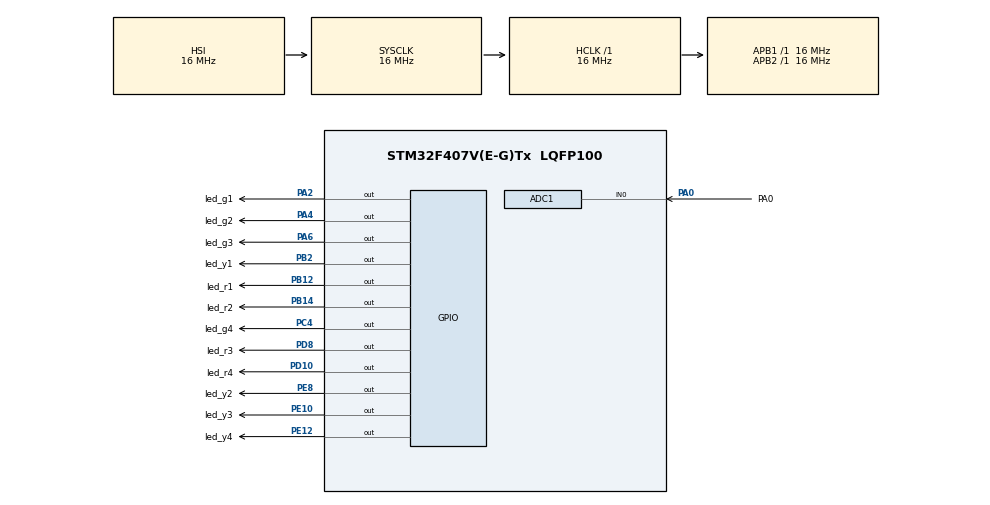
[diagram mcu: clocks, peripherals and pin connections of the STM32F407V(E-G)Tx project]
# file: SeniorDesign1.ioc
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ADC1.Channel-1\#ChannelRegularConversion=ADC_CHANNEL_0
ADC1.ContinuousConvMode=ENABLE
ADC1.NbrOfConversionFlag=1
ADC1.Rank-1\#ChannelRegularConversion=1
ADC1.SamplingTime-1\#ChannelRegularConversion=ADC_SAMPLETIME_3CYCLES
ADC1.ScanConvMode=ENABLE
ADC1.master=1
Dma.ADC1.0.Direction=DMA_PERIPH_TO_MEMORY
Dma.ADC1.0.FIFOMode=DMA_FIFOMODE_DISABLE
Dma.ADC1.0.Instance=DMA2_Stream0
Dma.ADC1.0.MemDataAlignment=DMA_MDATAALIGN_HALFWORD
Dma.ADC1.0.MemInc=DMA_MINC_ENABLE
Dma.ADC1.0.Mode=DMA_NORMAL
Dma.ADC1.0.PeriphDataAlignment=DMA_PDATAALIGN_HALFWORD
Dma.ADC1.0.PeriphInc=DMA_PINC_DISABLE
Dma.ADC1.0.Priority=DMA_PRIORITY_LOW
Dma.Request0=ADC1
FREERTOS.Tasks01=defaultair,24,128,StartAirTask,As weak,NULL,Static,airTaskBuffer,airTaskControlBlock
Mcu.Family=STM32F4
Mcu.Name=STM32F407V(E-G)Tx
Mcu.Package=LQFP100
NVIC.DMA2_Stream0_IRQn=true\:5\:0\:false\:false\:true\:true\:false\:true
NVIC.PriorityGroup=NVIC_PRIORITYGROUP_4
PA0-WKUP.GPIO_Label=PA0
PA0-WKUP.Signal=ADCx_IN0
PA2.GPIO_Label=led_g1
PA2.Signal=GPIO_Output
PA4.GPIO_Label=led_g2
PA4.Signal=GPIO_Output
PA6.GPIO_Label=led_g3
PA6.Signal=GPIO_Output
PB12.GPIO_Label=led_r1
PB12.Signal=GPIO_Output
PB14.GPIO_Label=led_r2
PB14.Signal=GPIO_Output
PB2.GPIO_Label=led_y1
PB2.Signal=GPIO_Output
PC4.GPIO_Label=led_g4
PC4.Signal=GPIO_Output
PD10.GPIO_Label=led_r4
PD10.Signal=GPIO_Output
PD8.GPIO_Label=led_r3
PD8.Signal=GPIO_Output
PE10.GPIO_Label=led_y3
PE10.Signal=GPIO_Output
PE12.GPIO_Label=led_y4
PE12.Signal=GPIO_Output
PE8.GPIO_Label=led_y2
PE8.Signal=GPIO_Output
ProjectManager.HeapSize=0x200
ProjectManager.StackSize=0x400
ProjectManager.TargetToolchain=STM32CubeIDE
RCC.AHBFreq_Value=16000000
RCC.APB1Freq_Value=16000000
RCC.APB2Freq_Value=16000000
RCC.CortexFreq_Value=16000000
RCC.HSE_VALUE=25000000
RCC.HSI_VALUE=16000000
RCC.LSE_VALUE=32768
RCC.SYSCLKFreq_VALUE=16000000
RCC.VCOOutputFreq_Value=192000000
SH.ADCx_IN0.0=ADC1_IN0,IN0
VP_FREERTOS_VS_CMSIS_V2.Mode=CMSIS_V2
board=STM32F407G-DISC1

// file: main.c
/* USER CODE BEGIN Header */
/**
  ******************************************************************************
  * @file           : main.c
  * @brief          : Main program body
  ******************************************************************************
  * @attention
  *
  * <h2><center>&copy; Copyright (c) 2020 STMicroelectronics.
  * All rights reserved.</center></h2>
  *
  * This software component is licensed by ST under BSD 3-Clause license,
  * the "License"; You may not use this file except in compliance with the
  * License. You may obtain a copy of the License at:
  *                        opensource.org/licenses/BSD-3-Clause
  *
  ******************************************************************************
  */
/* USER CODE END Header */

#include "main.h"
#include "cmsis_os.h"

typedef StaticTask_t osStaticThreadDef_t;

ADC_HandleTypeDef hadc1;
DMA_HandleTypeDef hdma_adc1;

/* Definitions for defaultair */
osThreadId_t defaultairHandle;
uint32_t airTaskBuffer[ 128 ];
osStaticThreadDef_t airTaskControlBlock;
const osThreadAttr_t defaultair_attributes = {
  .name = "defaultair",
  .stack_mem = &airTaskBuffer[0],
  .stack_size = sizeof(airTaskBuffer),
  .cb_mem = &airTaskControlBlock,
  .cb_size = sizeof(airTaskControlBlock),
  .priority = (osPriority_t) osPriorityNormal,
};

void SystemClock_Config(void);
static void MX_GPIO_Init(void);
static void MX_DMA_Init(void);
static void MX_ADC1_Init(void);
void StartAirTask(void *argument);

/* USER CODE BEGIN 0 */
uint32_t g_ADCValue[1];
int adcInt;
/* USER CODE END 0 */

int main(void)
{

  /* MCU Configuration--------------------------------------------------------*/

  /* Reset of all peripherals, Initializes the Flash interface and the Systick. */
  HAL_Init();

  /* Configure the system clock */
  SystemClock_Config();

  /* Initialize all configured peripherals */
  MX_GPIO_Init();
  MX_DMA_Init();
  MX_ADC1_Init();

  /* Init scheduler */
  osKernelInitialize();

  /* Create the thread(s) */
  /* creation of defaultair */
  defaultairHandle = osThreadNew(StartAirTask, NULL, &defaultair_attributes);

  /* Start scheduler */
  osKernelStart();

  /* We should never get here as control is now taken by the scheduler */
  /* Infinite loop */
  /* USER CODE BEGIN WHILE */
  uint32_t g_ADCValue;
  HAL_ADC_Start(&hadc1);
  //int x = 0;
  while (1)
  {
    /* USER CODE END WHILE */

  }
}

void SystemClock_Config(void)
{
  RCC_OscInitTypeDef RCC_OscInitStruct = {0};
  RCC_ClkInitTypeDef RCC_ClkInitStruct = {0};

  /** Configure the main internal regulator output voltage
  */
  __HAL_RCC_PWR_CLK_ENABLE();
  __HAL_PWR_VOLTAGESCALING_CONFIG(PWR_REGULATOR_VOLTAGE_SCALE1);
  /** Initializes the CPU, AHB and APB busses clocks
  */
  RCC_OscInitStruct.OscillatorType = RCC_OSCILLATORTYPE_HSI;
  RCC_OscInitStruct.HSIState = RCC_HSI_ON;
  RCC_OscInitStruct.HSICalibrationValue = RCC_HSICALIBRATION_DEFAULT;
  RCC_OscInitStruct.PLL.PLLState = RCC_PLL_NONE;
  if (HAL_RCC_OscConfig(&RCC_OscInitStruct) != HAL_OK)
  {
    Error_Handler();
  }
  /** Initializes the CPU, AHB and APB busses clocks
  */
  RCC_ClkInitStruct.ClockType = RCC_CLOCKTYPE_HCLK|RCC_CLOCKTYPE_SYSCLK
                              |RCC_CLOCKTYPE_PCLK1|RCC_CLOCKTYPE_PCLK2;
  RCC_ClkInitStruct.SYSCLKSource = RCC_SYSCLKSOURCE_HSI;
  RCC_ClkInitStruct.AHBCLKDivider = RCC_SYSCLK_DIV1;
  RCC_ClkInitStruct.APB1CLKDivider = RCC_HCLK_DIV1;
  RCC_ClkInitStruct.APB2CLKDivider = RCC_HCLK_DIV1;

  if (HAL_RCC_ClockConfig(&RCC_ClkInitStruct, FLASH_LATENCY_0) != HAL_OK)
  {
    Error_Handler();
  }
}

static void MX_ADC1_Init(void)
{

  /* USER CODE BEGIN ADC1_Init 0 */
	__HAL_RCC_ADC1_CLK_ENABLE();
  /* USER CODE END ADC1_Init 0 */

  ADC_ChannelConfTypeDef sConfig = {0};

  /** Configure the global features of the ADC (Clock, Resolution, Data Alignment and number of conversion)
  */
  hadc1.Instance = ADC1;
  hadc1.Init.ClockPrescaler = ADC_CLOCK_SYNC_PCLK_DIV2;
  hadc1.Init.Resolution = ADC_RESOLUTION_12B;
  hadc1.Init.ScanConvMode = ENABLE;
  hadc1.Init.ContinuousConvMode = ENABLE;
  hadc1.Init.DiscontinuousConvMode = DISABLE;
  hadc1.Init.ExternalTrigConvEdge = ADC_EXTERNALTRIGCONVEDGE_NONE;
  hadc1.Init.ExternalTrigConv = ADC_SOFTWARE_START;
  hadc1.Init.DataAlign = ADC_DATAALIGN_RIGHT;
  hadc1.Init.NbrOfConversion = 1;
  hadc1.Init.DMAContinuousRequests = DISABLE;
  hadc1.Init.EOCSelection = ADC_EOC_SINGLE_CONV;
  if (HAL_ADC_Init(&hadc1) != HAL_OK)
  {
    Error_Handler();
  }
  /** Configure for the selected ADC regular channel its corresponding rank in the sequencer and its sample time.
  */
  sConfig.Channel = ADC_CHANNEL_0;
  sConfig.Rank = 1;
  sConfig.SamplingTime = ADC_SAMPLETIME_3CYCLES;
  if (HAL_ADC_ConfigChannel(&hadc1, &sConfig) != HAL_OK)
  {
    Error_Handler();
  }

}

static void MX_DMA_Init(void)
{

  /* DMA controller clock enable */
  __HAL_RCC_DMA2_CLK_ENABLE();

  /* DMA interrupt init */
  /* DMA2_Stream0_IRQn interrupt configuration */
  HAL_NVIC_SetPriority(DMA2_Stream0_IRQn, 5, 0);
  HAL_NVIC_EnableIRQ(DMA2_Stream0_IRQn);

}

static void MX_GPIO_Init(void)
{
  GPIO_InitTypeDef GPIO_InitStruct = {0};

  /* GPIO Ports Clock Enable */
  __HAL_RCC_GPIOA_CLK_ENABLE();
  __HAL_RCC_GPIOC_CLK_ENABLE();
  __HAL_RCC_GPIOB_CLK_ENABLE();
  __HAL_RCC_GPIOE_CLK_ENABLE();
  __HAL_RCC_GPIOD_CLK_ENABLE();

  /*Configure GPIO pin Output Level */
  HAL_GPIO_WritePin(GPIOA, led_g1_Pin|led_g2_Pin|led_g3_Pin, GPIO_PIN_RESET);

  /*Configure GPIO pin Output Level */
  HAL_GPIO_WritePin(led_g4_GPIO_Port, led_g4_Pin, GPIO_PIN_RESET);

  /*Configure GPIO pin Output Level */
  HAL_GPIO_WritePin(GPIOB, led_y1_Pin|led_r1_Pin|led_r2_Pin, GPIO_PIN_RESET);

  /*Configure GPIO pin Output Level */
  HAL_GPIO_WritePin(GPIOE, led_y2_Pin|led_y3_Pin|led_y4_Pin, GPIO_PIN_RESET);

  /*Configure GPIO pin Output Level */
  HAL_GPIO_WritePin(GPIOD, led_r3_Pin|led_r4_Pin, GPIO_PIN_RESET);

  /*Configure GPIO pins : led_g1_Pin led_g2_Pin led_g3_Pin */
  GPIO_InitStruct.Pin = led_g1_Pin|led_g2_Pin|led_g3_Pin;
  GPIO_InitStruct.Mode = GPIO_MODE_OUTPUT_PP;
  GPIO_InitStruct.Pull = GPIO_NOPULL;
  GPIO_InitStruct.Speed = GPIO_SPEED_FREQ_LOW;
  HAL_GPIO_Init(GPIOA, &GPIO_InitStruct);

  /*Configure GPIO pin : led_g4_Pin */
  GPIO_InitStruct.Pin = led_g4_Pin;
  GPIO_InitStruct.Mode = GPIO_MODE_OUTPUT_PP;
  GPIO_InitStruct.Pull = GPIO_NOPULL;
  GPIO_InitStruct.Speed = GPIO_SPEED_FREQ_LOW;
  HAL_GPIO_Init(led_g4_GPIO_Port, &GPIO_InitStruct);

  /*Configure GPIO pins : led_y1_Pin led_r1_Pin led_r2_Pin */
  GPIO_InitStruct.Pin = led_y1_Pin|led_r1_Pin|led_r2_Pin;
  GPIO_InitStruct.Mode = GPIO_MODE_OUTPUT_PP;
  GPIO_InitStruct.Pull = GPIO_NOPULL;
  GPIO_InitStruct.Speed = GPIO_SPEED_FREQ_LOW;
  HAL_GPIO_Init(GPIOB, &GPIO_InitStruct);

  /*Configure GPIO pins : led_y2_Pin led_y3_Pin led_y4_Pin */
  GPIO_InitStruct.Pin = led_y2_Pin|led_y3_Pin|led_y4_Pin;
  GPIO_InitStruct.Mode = GPIO_MODE_OUTPUT_PP;
  GPIO_InitStruct.Pull = GPIO_NOPULL;
  GPIO_InitStruct.Speed = GPIO_SPEED_FREQ_LOW;
  HAL_GPIO_Init(GPIOE, &GPIO_InitStruct);

  /*Configure GPIO pins : led_r3_Pin led_r4_Pin */
  GPIO_InitStruct.Pin = led_r3_Pin|led_r4_Pin;
  GPIO_InitStruct.Mode = GPIO_MODE_OUTPUT_PP;
  GPIO_InitStruct.Pull = GPIO_NOPULL;
  GPIO_InitStruct.Speed = GPIO_SPEED_FREQ_LOW;
  HAL_GPIO_Init(GPIOD, &GPIO_InitStruct);

}

__weak void StartAirTask(void *argument)
{
  for(;;)
  {
    osDelay(1);
  }
}

void Error_Handler(void)
{
}

/************************ (C) COPYRIGHT STMicroelectronics *****END OF FILE****/
